# DMASS_INTAGGR_0_INTAGGR_UNMAP_48180000h register map
Vendor: Texas Instruments
Peripheral module from a debugger description file (folder am62D).
Registers are 64-bit, read-write, reset 0xFFFF unless marked. A register's access mark holds for its fields unless they carry their own. Offsets are as the file gives them; lines under a group give offsets from that group; [hi:lo] are bit positions; {n}, {i} and the like mark numbered series; 'fields as' and 'values as' point back to an identical list; <NAME> marks a mode.

## intaggr_unmap
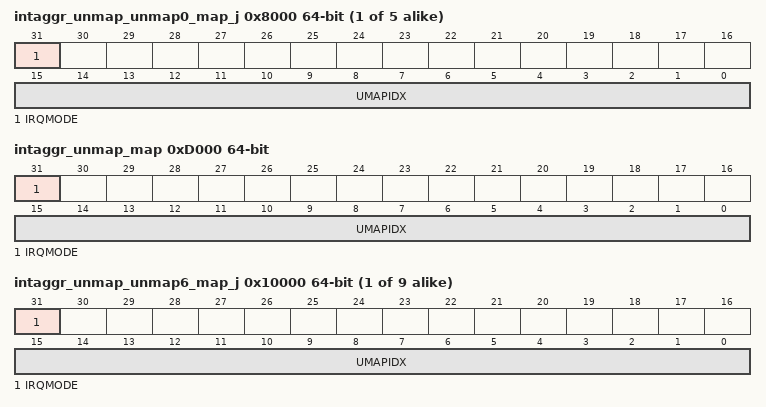
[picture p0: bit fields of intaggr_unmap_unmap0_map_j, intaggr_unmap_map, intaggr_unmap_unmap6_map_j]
{0x8000+0x1000*i} intaggr_unmap_unmap{i}_map_j (i=0..4) — The Global Event Mapping register controls the egress global event index for this unmapped event. This register may also be optionally used to directly set an interrupt status bit by using the irqmode flag.
  [31] IRQMODE — IRQ Mode Flag. When set, this register act like a mapper with bitnum in 5:0 and regnum in 14:6. Reset Source: srst_n
  [15:0] UMAPIDX — Global event index. This field specifies the index of the outgoing global event. Set to 0xFFFF to disable. Reset Source: srst_n
0xD000 intaggr_unmap_unmap5 32-bit access not given reset not defined
0xD000 intaggr_unmap_map — The Global Event Mapping register controls the egress global event index for this unmapped event. This register may also be optionally used to directly set an interrupt status bit by using the irqmode flag.
  fields as intaggr_unmap_unmap0_map_j
{0xA000+0x1000*i} intaggr_unmap_unmap{i}_map_j (i=6..14) — The Global Event Mapping register controls the egress global event index for this unmapped event. This register may also be optionally used to directly set an interrupt status bit by using the irqmode flag.
  fields as intaggr_unmap_unmap0_map_j
